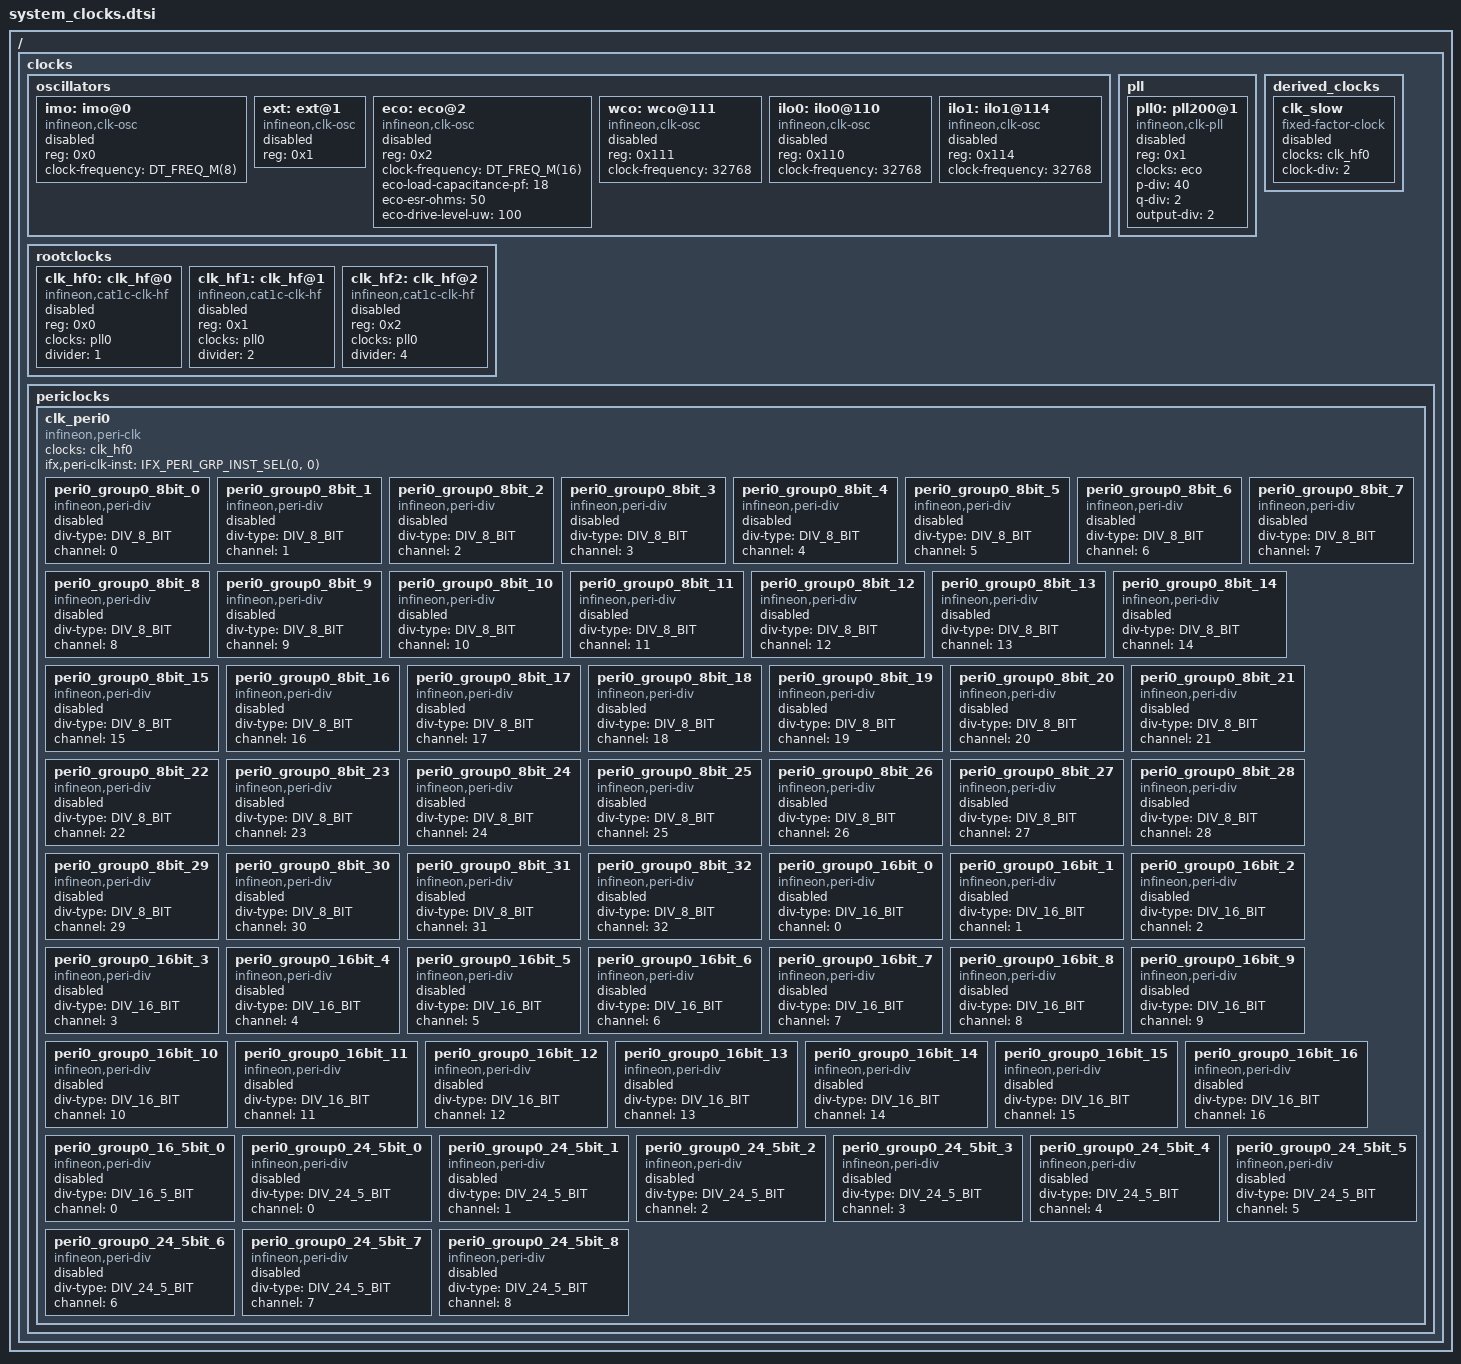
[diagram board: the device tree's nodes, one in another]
/*
 * Copyright (c) 2026 Linumiz
 * Copyright (c) 2026 Infineon Technologies AG
 * SPDX-License-Identifier: Apache-2.0
 */

#define DIV_8_BIT    00
#define DIV_16_BIT   01
#define DIV_16_5_BIT 02
#define DIV_24_5_BIT 03

#include <freq.h>

/ {
	clocks: clocks {
		oscillators: oscillators {
			#address-cells = <1>;
			#size-cells = <0>;

			imo: imo@0 {
				compatible = "infineon,clk-osc";
				reg = <0x0>;
				#clock-cells = <0>;
				clock-frequency = <DT_FREQ_M(8)>;
				status = "disabled";
			};

			ext: ext@1 {
				compatible = "infineon,clk-osc";
				reg = <0x1>;
				#clock-cells = <0>;
				status = "disabled";
			};

			eco: eco@2 {
				compatible = "infineon,clk-osc";
				reg = <0x2>;
				#clock-cells = <0>;
				clock-frequency = <DT_FREQ_M(16)>;
				eco-load-capacitance-pf = <18>;
				eco-esr-ohms = <50>;
				eco-drive-level-uw = <100>;
				status = "disabled";
			};

			wco: wco@111 {
				compatible = "infineon,clk-osc";
				reg = <0x111>;
				#clock-cells = <0>;
				clock-frequency = <32768>;
				status = "disabled";
			};

			ilo0: ilo0@110 {
				compatible = "infineon,clk-osc";
				reg = <0x110>;
				#clock-cells = <0>;
				clock-frequency = <32768>;
				status = "disabled";
			};

			ilo1: ilo1@114 {
				compatible = "infineon,clk-osc";
				reg = <0x114>;
				#clock-cells = <0>;
				clock-frequency = <32768>;
				status = "disabled";
			};
		};

		pll {
			#address-cells = <1>;
			#size-cells = <0>;

			pll0: pll200@1 {
				compatible = "infineon,clk-pll";
				reg = <0x1>;
				#clock-cells = <0>;
				clocks = <&eco>;
				p-div = <40>;
				q-div = <2>;
				output-div = <2>;
				status = "disabled";
			};
		};

		rootclocks {
			#address-cells = <1>;
			#size-cells = <0>;

			clk_hf0: clk_hf@0 {
				compatible = "infineon,cat1c-clk-hf";
				reg = <0x0>;
				#clock-cells = <0>;
				clocks = <&pll0>;
				divider = <1>;
				status = "disabled";
			};

			clk_hf1: clk_hf@1 {
				compatible = "infineon,cat1c-clk-hf";
				reg = <0x1>;
				#clock-cells = <0>;
				clocks = <&pll0>;
				divider = <2>;
				status = "disabled";
			};

			clk_hf2: clk_hf@2 {
				compatible = "infineon,cat1c-clk-hf";
				reg = <0x2>;
				#clock-cells = <0>;
				clocks = <&pll0>;
				divider = <4>;
				status = "disabled";
			};
		};

		derived_clocks {
			clk_slow: clk_slow {
				compatible = "fixed-factor-clock";
				clocks = <&clk_hf0>;
				#clock-cells = <0>;
				clock-div = <2>;
				status = "disabled";
			};
		};

		periclocks {
			clk_peri0: clk_peri0 {
				compatible = "infineon,peri-clk";
				clocks = <&clk_hf0>;
				ifx,peri-clk-inst = <IFX_PERI_GRP_INST_SEL(0, 0)>;

				peri0_group0_8bit_0: peri0_group0_8bit_0 {
					compatible = "infineon,peri-div";
					#clock-cells = <0>;
					div-type = <DIV_8_BIT>;
					channel = <0>;
					status = "disabled";
				};

				peri0_group0_8bit_1: peri0_group0_8bit_1 {
					compatible = "infineon,peri-div";
					#clock-cells = <0>;
					div-type = <DIV_8_BIT>;
					channel = <1>;
					status = "disabled";
				};

				peri0_group0_8bit_2: peri0_group0_8bit_2 {
					compatible = "infineon,peri-div";
					#clock-cells = <0>;
					div-type = <DIV_8_BIT>;
					channel = <2>;
					status = "disabled";
				};

				peri0_group0_8bit_3: peri0_group0_8bit_3 {
					compatible = "infineon,peri-div";
					#clock-cells = <0>;
					div-type = <DIV_8_BIT>;
					channel = <3>;
					status = "disabled";
				};

				peri0_group0_8bit_4: peri0_group0_8bit_4 {
					compatible = "infineon,peri-div";
					#clock-cells = <0>;
					div-type = <DIV_8_BIT>;
					channel = <4>;
					status = "disabled";
				};

				peri0_group0_8bit_5: peri0_group0_8bit_5 {
					compatible = "infineon,peri-div";
					#clock-cells = <0>;
					div-type = <DIV_8_BIT>;
					channel = <5>;
					status = "disabled";
				};

				peri0_group0_8bit_6: peri0_group0_8bit_6 {
					compatible = "infineon,peri-div";
					#clock-cells = <0>;
					div-type = <DIV_8_BIT>;
					channel = <6>;
					status = "disabled";
				};

				peri0_group0_8bit_7: peri0_group0_8bit_7 {
					compatible = "infineon,peri-div";
					#clock-cells = <0>;
					div-type = <DIV_8_BIT>;
					channel = <7>;
					status = "disabled";
				};

				peri0_group0_8bit_8: peri0_group0_8bit_8 {
					compatible = "infineon,peri-div";
					#clock-cells = <0>;
					div-type = <DIV_8_BIT>;
					channel = <8>;
					status = "disabled";
				};

				peri0_group0_8bit_9: peri0_group0_8bit_9 {
					compatible = "infineon,peri-div";
					#clock-cells = <0>;
					div-type = <DIV_8_BIT>;
					channel = <9>;
					status = "disabled";
				};

				peri0_group0_8bit_10: peri0_group0_8bit_10 {
					compatible = "infineon,peri-div";
					#clock-cells = <0>;
					div-type = <DIV_8_BIT>;
					channel = <10>;
					status = "disabled";
				};

				peri0_group0_8bit_11: peri0_group0_8bit_11 {
					compatible = "infineon,peri-div";
					#clock-cells = <0>;
					div-type = <DIV_8_BIT>;
					channel = <11>;
					status = "disabled";
				};

				peri0_group0_8bit_12: peri0_group0_8bit_12 {
					compatible = "infineon,peri-div";
					#clock-cells = <0>;
					div-type = <DIV_8_BIT>;
					channel = <12>;
					status = "disabled";
				};

				peri0_group0_8bit_13: peri0_group0_8bit_13 {
					compatible = "infineon,peri-div";
					#clock-cells = <0>;
					div-type = <DIV_8_BIT>;
					channel = <13>;
					status = "disabled";
				};

				peri0_group0_8bit_14: peri0_group0_8bit_14 {
					compatible = "infineon,peri-div";
					#clock-cells = <0>;
					div-type = <DIV_8_BIT>;
					channel = <14>;
					status = "disabled";
				};

				peri0_group0_8bit_15: peri0_group0_8bit_15 {
					compatible = "infineon,peri-div";
					#clock-cells = <0>;
					div-type = <DIV_8_BIT>;
					channel = <15>;
					status = "disabled";
				};

				peri0_group0_8bit_16: peri0_group0_8bit_16 {
					compatible = "infineon,peri-div";
					#clock-cells = <0>;
					div-type = <DIV_8_BIT>;
					channel = <16>;
					status = "disabled";
				};

				peri0_group0_8bit_17: peri0_group0_8bit_17 {
					compatible = "infineon,peri-div";
					#clock-cells = <0>;
					div-type = <DIV_8_BIT>;
					channel = <17>;
					status = "disabled";
				};

				peri0_group0_8bit_18: peri0_group0_8bit_18 {
					compatible = "infineon,peri-div";
					#clock-cells = <0>;
					div-type = <DIV_8_BIT>;
					channel = <18>;
					status = "disabled";
				};

				peri0_group0_8bit_19: peri0_group0_8bit_19 {
					compatible = "infineon,peri-div";
					#clock-cells = <0>;
					div-type = <DIV_8_BIT>;
					channel = <19>;
					status = "disabled";
				};

				peri0_group0_8bit_20: peri0_group0_8bit_20 {
					compatible = "infineon,peri-div";
					#clock-cells = <0>;
					div-type = <DIV_8_BIT>;
					channel = <20>;
					status = "disabled";
				};

				peri0_group0_8bit_21: peri0_group0_8bit_21 {
					compatible = "infineon,peri-div";
					#clock-cells = <0>;
					div-type = <DIV_8_BIT>;
					channel = <21>;
					status = "disabled";
				};

				peri0_group0_8bit_22: peri0_group0_8bit_22 {
					compatible = "infineon,peri-div";
					#clock-cells = <0>;
					div-type = <DIV_8_BIT>;
					channel = <22>;
					status = "disabled";
				};

				peri0_group0_8bit_23: peri0_group0_8bit_23 {
					compatible = "infineon,peri-div";
					#clock-cells = <0>;
					div-type = <DIV_8_BIT>;
					channel = <23>;
					status = "disabled";
				};

				peri0_group0_8bit_24: peri0_group0_8bit_24 {
					compatible = "infineon,peri-div";
					#clock-cells = <0>;
					div-type = <DIV_8_BIT>;
					channel = <24>;
					status = "disabled";
				};

				peri0_group0_8bit_25: peri0_group0_8bit_25 {
					compatible = "infineon,peri-div";
					#clock-cells = <0>;
					div-type = <DIV_8_BIT>;
					channel = <25>;
					status = "disabled";
				};

				peri0_group0_8bit_26: peri0_group0_8bit_26 {
					compatible = "infineon,peri-div";
					#clock-cells = <0>;
					div-type = <DIV_8_BIT>;
					channel = <26>;
					status = "disabled";
				};

				peri0_group0_8bit_27: peri0_group0_8bit_27 {
					compatible = "infineon,peri-div";
					#clock-cells = <0>;
					div-type = <DIV_8_BIT>;
					channel = <27>;
					status = "disabled";
				};

				peri0_group0_8bit_28: peri0_group0_8bit_28 {
					compatible = "infineon,peri-div";
					#clock-cells = <0>;
					div-type = <DIV_8_BIT>;
					channel = <28>;
					status = "disabled";
				};

				peri0_group0_8bit_29: peri0_group0_8bit_29 {
					compatible = "infineon,peri-div";
					#clock-cells = <0>;
					div-type = <DIV_8_BIT>;
					channel = <29>;
					status = "disabled";
				};

				peri0_group0_8bit_30: peri0_group0_8bit_30 {
					compatible = "infineon,peri-div";
					#clock-cells = <0>;
					div-type = <DIV_8_BIT>;
					channel = <30>;
					status = "disabled";
				};

				peri0_group0_8bit_31: peri0_group0_8bit_31 {
					compatible = "infineon,peri-div";
					#clock-cells = <0>;
					div-type = <DIV_8_BIT>;
					channel = <31>;
					status = "disabled";
				};

				peri0_group0_8bit_32: peri0_group0_8bit_32 {
					compatible = "infineon,peri-div";
					#clock-cells = <0>;
					div-type = <DIV_8_BIT>;
					channel = <32>;
					status = "disabled";
				};

				peri0_group0_16bit_0: peri0_group0_16bit_0 {
					compatible = "infineon,peri-div";
					#clock-cells = <0>;
					div-type = <DIV_16_BIT>;
					channel = <0>;
					status = "disabled";
				};

				peri0_group0_16bit_1: peri0_group0_16bit_1 {
					compatible = "infineon,peri-div";
					#clock-cells = <0>;
					div-type = <DIV_16_BIT>;
					channel = <1>;
					status = "disabled";
				};

				peri0_group0_16bit_2: peri0_group0_16bit_2 {
					compatible = "infineon,peri-div";
					#clock-cells = <0>;
					div-type = <DIV_16_BIT>;
					channel = <2>;
					status = "disabled";
				};

				peri0_group0_16bit_3: peri0_group0_16bit_3 {
					compatible = "infineon,peri-div";
					#clock-cells = <0>;
					div-type = <DIV_16_BIT>;
					channel = <3>;
					status = "disabled";
				};

				peri0_group0_16bit_4: peri0_group0_16bit_4 {
					compatible = "infineon,peri-div";
					#clock-cells = <0>;
					div-type = <DIV_16_BIT>;
					channel = <4>;
					status = "disabled";
				};

				peri0_group0_16bit_5: peri0_group0_16bit_5 {
					compatible = "infineon,peri-div";
					#clock-cells = <0>;
					div-type = <DIV_16_BIT>;
					channel = <5>;
					status = "disabled";
				};

				peri0_group0_16bit_6: peri0_group0_16bit_6 {
					compatible = "infineon,peri-div";
					#clock-cells = <0>;
					div-type = <DIV_16_BIT>;
					channel = <6>;
					status = "disabled";
				};

				peri0_group0_16bit_7: peri0_group0_16bit_7 {
					compatible = "infineon,peri-div";
					#clock-cells = <0>;
					div-type = <DIV_16_BIT>;
					channel = <7>;
					status = "disabled";
				};

				peri0_group0_16bit_8: peri0_group0_16bit_8 {
					compatible = "infineon,peri-div";
					#clock-cells = <0>;
					div-type = <DIV_16_BIT>;
					channel = <8>;
					status = "disabled";
				};

				peri0_group0_16bit_9: peri0_group0_16bit_9 {
					compatible = "infineon,peri-div";
					#clock-cells = <0>;
					div-type = <DIV_16_BIT>;
					channel = <9>;
					status = "disabled";
				};

				peri0_group0_16bit_10: peri0_group0_16bit_10 {
					compatible = "infineon,peri-div";
					#clock-cells = <0>;
					div-type = <DIV_16_BIT>;
					channel = <10>;
					status = "disabled";
				};

				peri0_group0_16bit_11: peri0_group0_16bit_11 {
					compatible = "infineon,peri-div";
					#clock-cells = <0>;
					div-type = <DIV_16_BIT>;
					channel = <11>;
					status = "disabled";
				};

				peri0_group0_16bit_12: peri0_group0_16bit_12 {
					compatible = "infineon,peri-div";
					#clock-cells = <0>;
					div-type = <DIV_16_BIT>;
					channel = <12>;
					status = "disabled";
				};

				peri0_group0_16bit_13: peri0_group0_16bit_13 {
					compatible = "infineon,peri-div";
					#clock-cells = <0>;
					div-type = <DIV_16_BIT>;
					channel = <13>;
					status = "disabled";
				};

				peri0_group0_16bit_14: peri0_group0_16bit_14 {
					compatible = "infineon,peri-div";
					#clock-cells = <0>;
					div-type = <DIV_16_BIT>;
					channel = <14>;
					status = "disabled";
				};

				peri0_group0_16bit_15: peri0_group0_16bit_15 {
					compatible = "infineon,peri-div";
					#clock-cells = <0>;
					div-type = <DIV_16_BIT>;
					channel = <15>;
					status = "disabled";
				};

				peri0_group0_16bit_16: peri0_group0_16bit_16 {
					compatible = "infineon,peri-div";
					#clock-cells = <0>;
					div-type = <DIV_16_BIT>;
					channel = <16>;
					status = "disabled";
				};

				peri0_group0_16_5bit_0: peri0_group0_16_5bit_0 {
					compatible = "infineon,peri-div";
					#clock-cells = <0>;
					div-type = <DIV_16_5_BIT>;
					channel = <0>;
					status = "disabled";
				};

				peri0_group0_24_5bit_0: peri0_group0_24_5bit_0 {
					compatible = "infineon,peri-div";
					#clock-cells = <0>;
					div-type = <DIV_24_5_BIT>;
					channel = <0>;
					status = "disabled";
				};

				peri0_group0_24_5bit_1: peri0_group0_24_5bit_1 {
					compatible = "infineon,peri-div";
					#clock-cells = <0>;
					div-type = <DIV_24_5_BIT>;
					channel = <1>;
					status = "disabled";
				};

				peri0_group0_24_5bit_2: peri0_group0_24_5bit_2 {
					compatible = "infineon,peri-div";
					#clock-cells = <0>;
					div-type = <DIV_24_5_BIT>;
					channel = <2>;
					status = "disabled";
				};

				peri0_group0_24_5bit_3: peri0_group0_24_5bit_3 {
					compatible = "infineon,peri-div";
					#clock-cells = <0>;
					div-type = <DIV_24_5_BIT>;
					channel = <3>;
					status = "disabled";
				};

				peri0_group0_24_5bit_4: peri0_group0_24_5bit_4 {
					compatible = "infineon,peri-div";
					#clock-cells = <0>;
					div-type = <DIV_24_5_BIT>;
					channel = <4>;
					status = "disabled";
				};

				peri0_group0_24_5bit_5: peri0_group0_24_5bit_5 {
					compatible = "infineon,peri-div";
					#clock-cells = <0>;
					div-type = <DIV_24_5_BIT>;
					channel = <5>;
					status = "disabled";
				};

				peri0_group0_24_5bit_6: peri0_group0_24_5bit_6 {
					compatible = "infineon,peri-div";
					#clock-cells = <0>;
					div-type = <DIV_24_5_BIT>;
					channel = <6>;
					status = "disabled";
				};

				peri0_group0_24_5bit_7: peri0_group0_24_5bit_7 {
					compatible = "infineon,peri-div";
					#clock-cells = <0>;
					div-type = <DIV_24_5_BIT>;
					channel = <7>;
					status = "disabled";
				};

				peri0_group0_24_5bit_8: peri0_group0_24_5bit_8 {
					compatible = "infineon,peri-div";
					#clock-cells = <0>;
					div-type = <DIV_24_5_BIT>;
					channel = <8>;
					status = "disabled";
				};
			};
		};
	};
};
